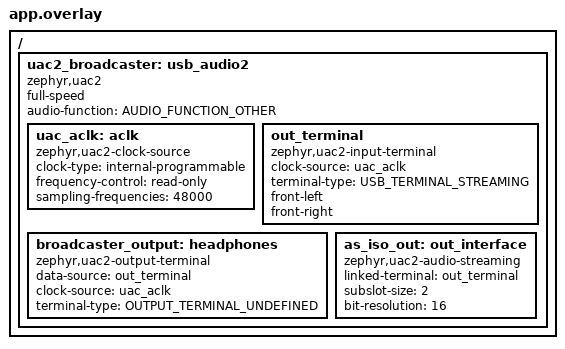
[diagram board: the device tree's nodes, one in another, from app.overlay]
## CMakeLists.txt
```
# SPDX-License-Identifier: Apache-2.0

cmake_minimum_required(VERSION 3.28.0)
find_package(Zephyr REQUIRED HINTS $ENV{ZEPHYR_BASE})
project(bap_broadcast_source)

target_sources(app PRIVATE
  src/main.c
)

target_sources_ifdef(CONFIG_AUDIO_INPUT_STREAM app PRIVATE src/audio_in.c)
target_sources_ifdef(CONFIG_CHAN_MAP_UPDATE app PRIVATE src/chan_map.c)
target_sources_ifdef(CONFIG_VS_FATAL_PRINT app PRIVATE src/vs_fatal.c)

if(CONFIG_AUDIO_INPUT_TIMED AND CONFIG_USE_USB_AUDIO_INPUT)
  target_sources(app PRIVATE src/usb_sof_nrf.c)
endif()

if(CONFIG_USE_USB_AUDIO_INPUT)
  include(${ZEPHYR_BASE}/samples/subsys/usb/common/common.cmake)
endif()
```

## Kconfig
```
# Copyright (c) 2023 Demant A/S
# Copyright (c) 2023 Nordic Semiconductor ASA
# SPDX-License-Identifier: Apache-2.0

mainmenu "Bluetooth: Broadcast Audio Source"

choice BAP_LC3_PRESET
	prompt "The BAP LC3 Preset to be used"
	default BAP_BROADCAST_16_2_1

config BAP_BROADCAST_16_2_1
	bool "BAP_LC3_BROADCAST_PRESET_16_2_1 preset"
	help
	  Using the BAP_LC3_BROADCAST_PRESET_16_2_1 preset.

config BAP_BROADCAST_24_2_1
	bool "BAP_LC3_BROADCAST_PRESET_24_2_1 preset"
	help
	  Using the BAP_LC3_BROADCAST_PRESET_24_2_1 preset.

config BAP_BROADCAST_48_2_1
	bool "BAP_LC3_BROADCAST_PRESET_48_2_1 preset"
	help
	  Using the BAP_LC3_BROADCAST_PRESET_48_2_1 preset.

endchoice

config ENABLE_LC3
	bool "Enable the LC3 codec"
	# By default let's enable it in the platforms we know are capable of supporting it
	default y
	depends on CPU_HAS_FPU && \
		(ARCH_POSIX || \
		SOC_COMPATIBLE_NRF52X || \
		SOC_COMPATIBLE_NRF5340_CPUAPP || \
		SOC_COMPATIBLE_NRF54LX || \
		SOC_MIMXRT1062 || \
		SOC_SERIES_ESP32S31)
	select LIBLC3
	select FPU

config ISO_PACKING_INTERLEAVED
	bool "Use interleaved packing"
	help
	  Use interleaved packing between BIS ISO stream subevents.

config USE_USB_AUDIO_INPUT
	bool "Use USB Audio as input"
	# By default, use the USB Audio path is disabled.
	depends on ENABLE_LC3
	select USB_DEVICE_STACK_NEXT
	select USBD_AUDIO2_CLASS

config BROADCAST_CODE
	string "The broadcast code (if any) to use for encrypted broadcast"
	default ""
	help
	   Setting a non-empty string for this option will encrypt the broadcast using this
	   string as the broadcast code. The length of the string shall be between 1 and 16 octets.

config STATIC_BROADCAST_ID
	bool "Use static broadcast ID"
	default y
	help
	   Enabling this option will make the application use static broadcast ID, as opposed to a
	   randomly generated one.

config BROADCAST_ID
	hex "The static broadcast ID to use"
	range 0x000000 0xFFFFFF
	depends on STATIC_BROADCAST_ID
	default 0x123456
	help
	   This is the 3-octet broadcast ID advertised if static broadcast IDs are enabled.

config BROADCAST_NAME
	string "Bluetooth broadcast name"
	default BT_DEVICE_NAME
	help
	   Bluetooth broadcast name. Can be used for scanning device that displays information on
	   the available broadcast sources. Name length range is 4 to 32.

# Source common USB sample options used to initialize new experimental USB device stack.
# The scope of these options is limited to USB samples in project tree,
# you cannot use them in your own application.
source "samples/subsys/usb/common/Kconfig.sample_usbd"

source "Kconfig.zephyr"
```

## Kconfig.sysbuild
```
# Copyright 2023 Nordic Semiconductor ASA
# SPDX-License-Identifier: Apache-2.0

source "share/sysbuild/Kconfig"

config NET_CORE_BOARD
	string
	default "nrf5340dk/nrf5340/cpunet" if "$(BOARD)" = "nrf5340dk"
	default "nrf5340_audio_dk/nrf5340/cpunet" if "$(BOARD)" = "nrf5340_audio_dk"
	default "nrf54h20dk/nrf54h20/cpurad" if "$(BOARD)" = "nrf54h20dk"
	default "nrf5340bsim/nrf5340/cpunet" if $(BOARD_TARGET_STRING) = "NRF5340BSIM_NRF5340_CPUAPP"

config NET_CORE_IMAGE_HCI_IPC
	bool "HCI IPC image on network core"
	default y
	depends on NET_CORE_BOARD != ""
```

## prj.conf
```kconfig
CONFIG_MAIN_STACK_SIZE=2048

CONFIG_BT=y
CONFIG_UTF8=y
CONFIG_BT_AUDIO=y
CONFIG_BT_ISO_BROADCASTER=y
CONFIG_BT_BAP_BROADCAST_SOURCE=y

# Allow simultaneous connectable advertising so that a remote central can
# connect while the broadcast source keeps streaming LE Audio. Three
# advertising sets run in parallel: the non-connectable extended broadcast
# audio set, a connectable extended set, and a connectable legacy set.
# Button 0 enables or disables the connectable advertising, off at boot.
CONFIG_BT_PERIPHERAL=y
CONFIG_BT_MAX_CONN=2
CONFIG_BT_EXT_ADV_MAX_ADV_SET=3

# Continuous active extended scanning, toggled by button 2 and off at boot.
# Its auxiliary channel receptions provide channel metrics for the channel map.
CONFIG_BT_OBSERVER=y

# Host ACL buffers to match the Controller maximum data length
CONFIG_BT_BUF_ACL_RX_SIZE=255
CONFIG_BT_BUF_ACL_TX_SIZE=251

CONFIG_BT_ISO_MAX_CHAN=2
CONFIG_BT_BAP_BROADCAST_SRC_STREAM_COUNT=2
# Two streams in one subgroup (stereo)
CONFIG_BT_BAP_BROADCAST_SRC_SUBGROUP_COUNT=1

# Uncomment below to use Broadcast ISO interleaved packing
# CONFIG_ISO_PACKING_INTERLEAVED=y

CONFIG_BT_ISO_TX_BUF_COUNT=6
CONFIG_BT_ISO_TX_MTU=155

CONFIG_BT_DEVICE_NAME="Broadcast Audio Source"

CONFIG_LOG=y
CONFIG_LOG_BUFFER_SIZE=4096

CONFIG_ASSERT=y
```

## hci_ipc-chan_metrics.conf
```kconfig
# Channel metrics vendor-specific event, used to update the channel map
CONFIG_BT_CTLR_CHAN_METRICS_EVENT=y
```

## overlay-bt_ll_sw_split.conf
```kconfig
# Zephyr Bluetooth Controller
CONFIG_BT_LL_SW_SPLIT=y

# Zephyr Controller tested maximum advertising data that can be set in a single HCI command
CONFIG_BT_CTLR_ADV_DATA_LEN_MAX=191

# Enable support for Broadcast ISO in Zephyr Bluetooth Controller
CONFIG_BT_CTLR_ADV_ISO=y
CONFIG_BT_CTLR_ADV_ISO_SEQUENTIAL=y
CONFIG_BT_CTLR_ADV_ISO_INTERLEAVED=y

# Sufficient ISO PDU length for any BAP LC3 presets (155)
CONFIG_BT_CTLR_ADV_ISO_PDU_LEN_MAX=155

# Number of supported streams
CONFIG_BT_CTLR_ADV_ISO_STREAM_MAX=2
CONFIG_BT_CTLR_ISOAL_SOURCES=2

# Support the highest SDU size required by any BAP LC3 presets (155) + 8 bytes of HCI ISO Data
# packet overhead (the Packet_Sequence_Number, ISO_SDU_Length, Packet_Status_Flag fields; and
# the optional Time_Stamp field, if supplied)
CONFIG_BT_CTLR_ISO_TX_BUFFER_SIZE=163
CONFIG_BT_CTLR_ISO_TX_SDU_LEN_MAX=155

# Use minimal time reservation for advertising radio events, successfully fit 155 Byte stereo BAP
# 48_6_1 preset and extended advertisements :-)
# Use the below when advertising is started after advertising data has been set and the data will
# not be updated to large size once advertising has been started
CONFIG_BT_CTLR_ADVANCED_FEATURES=y
CONFIG_BT_CTLR_ADV_RESERVE_MAX=n
CONFIG_BT_CTLR_PERIPHERAL_RESERVE_MAX=n

# Use the below to have auxiliary PDUs dynamically be placed in-between ISO intervals and hence
# permit large BIG event lengths (and hence, possibility to have pre-transmissions)
CONFIG_BT_CTLR_ADV_SLOT_WINDOW=y
CONFIG_BT_CTLR_ADV_AUX_SLOT_WINDOW_DRIFT=y

CONFIG_BT_CTLR_ADV_ISO_RESERVE_MAX=n
CONFIG_BT_CTLR_ADV_ISO_SLOT_WINDOW_JITTER=y

CONFIG_BT_CTLR_LLL_PRIO=0
CONFIG_BT_CTLR_ULL_HIGH_PRIO=1
CONFIG_BT_CTLR_ULL_LOW_PRIO=2

CONFIG_BT_CTLR_LLL_PREPARE_AT_MARGIN=y
CONFIG_BT_CTLR_RADIO_TIMER_ISR=y
CONFIG_BT_CTLR_SW_SWITCH_SINGLE_TIMER=n

# Enable in-system tests and profiling
# CONFIG_BT_CTLR_TEST=y
# CONFIG_BT_CTLR_PROFILE_ISR=y

CONFIG_BT_CTLR_ASSERT_OPTIMIZE_FOR_SIZE=n

# Extended scanning in parallel with Broadcast ISO
CONFIG_BT_CTLR_SCAN_AUX_SET=3
CONFIG_BT_CTLR_SCAN_AUX_SYNC_RESERVE_MIN=y
CONFIG_BT_CTLR_SCAN_UNRESERVED=y
CONFIG_BT_CTLR_SCAN_SLOT_WINDOW=y

# Channel metrics vendor-specific event, used to update the channel map
CONFIG_BT_CTLR_CHAN_METRICS_EVENT=y
```

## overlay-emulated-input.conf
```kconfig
# Emulated USB host feeding the audio input path, for testing without USB hardware
CONFIG_AUDIO_INPUT_EMULATED=y
CONFIG_BAP_BROADCAST_8_2_1=y
```

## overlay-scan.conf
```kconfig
# Continuous active extended scanning from boot
CONFIG_SCAN_BACKGROUND=y
```

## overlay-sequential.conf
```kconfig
CONFIG_ISO_PACKING_INTERLEAVED=n
```

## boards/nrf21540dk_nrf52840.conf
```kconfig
# Use USB Audio as audio source
CONFIG_USE_USB_AUDIO_INPUT=y
CONFIG_SAMPLE_USBD_PRODUCT="USB Broadcast Audio nRF21540DK"

CONFIG_UDC_DRIVER_LOG_LEVEL_WRN=y
CONFIG_USBD_LOG_LEVEL_WRN=y
CONFIG_USBD_UAC2_LOG_LEVEL_WRN=y
```

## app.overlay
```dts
/*
 * Copyright (c) 2025 Nordic Semiconductor ASA
 *
 * SPDX-License-Identifier: Apache-2.0
 */

#include <zephyr/dt-bindings/usb/audio.h>

/ {
	uac2_broadcaster: usb_audio2 {
		compatible = "zephyr,uac2";
		full-speed;
		audio-function = <AUDIO_FUNCTION_OTHER>;
		status = "okay";

		/* Clock supporting 48KHz
		 *
		 * For simplicity we claim support for 48KHz only and then downsample if needed
		 */
		uac_aclk: aclk {
			compatible = "zephyr,uac2-clock-source";
			clock-type = "internal-programmable";
			frequency-control = "read-only";
			sampling-frequencies = <48000>;
		};

		/* USB Audio terminal from USB host to USB device */
		out_terminal: out_terminal {
			compatible = "zephyr,uac2-input-terminal";
			clock-source = <&uac_aclk>;
			terminal-type = <USB_TERMINAL_STREAMING>;
			front-left;
			front-right;
		};

		/* The broadcaster_output terminal defines what we are sending over Bluetooth */
		broadcaster_output: headphones {
			compatible = "zephyr,uac2-output-terminal";
			data-source = <&out_terminal>;
			clock-source = <&uac_aclk>;
			terminal-type = <OUTPUT_TERMINAL_UNDEFINED>;
		};

		as_iso_out: out_interface {
			compatible = "zephyr,uac2-audio-streaming";
			linked-terminal = <&out_terminal>;
			subslot-size = <2>;
			bit-resolution = <16>;
		};
	};
};
```

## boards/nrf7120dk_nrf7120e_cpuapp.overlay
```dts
/*
 * Copyright (c) 2026 Nordic Semiconductor ASA
 *
 * SPDX-License-Identifier: Apache-2.0
 */

#include "../app.overlay"
```

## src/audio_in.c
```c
/*
 * Copyright (c) 2025 Nordic Semiconductor ASA
 *
 * SPDX-License-Identifier: Apache-2.0
 *
 * Audio input path between an asynchronous 48 kHz stereo producer (USB host) and the ISO
 * stream consumer. The ISO stream is the clock master: the consumer takes one SDU frame per
 * channel each time the controller completes an SDU. The buffer fill level, sampled just
 * before each take, integrates the rate difference between producer and consumer and drives
 * a PI loop that sets the UAC2 explicit feedback value. If the host does not follow the
 * feedback, a single sample is dropped or repeated per SDU to keep the buffer within bounds.
 *
 * With CONFIG_AUDIO_INPUT_TIMED the USB SOF times and the SDU transmission times share the
 * controller time base. The feedback value is then the measured number of samples per SOF
 * period at the ISO stream rate, and a slow proportional loop holds the buffer level at the
 * nominal encode time of each SDU, interpolated from the SOF timeline, on the target. This
 * level is free of USB packet and thread scheduling jitter, so the buffer stays at its target
 * without dropped or repeated samples.
 */

#include <errno.h>
#include <stdbool.h>
#include <stddef.h>
#include <stdint.h>
#include <string.h>

#include <zephyr/kernel.h>
#include <zephyr/sys/atomic.h>
#include <zephyr/sys/printk.h>
#include <zephyr/sys/ring_buffer.h>
#include <zephyr/sys/util.h>

#if defined(CONFIG_AUDIO_INPUT_TIMED)
#include <zephyr/drivers/timer/nrf_grtc_timer.h>
#endif /* CONFIG_AUDIO_INPUT_TIMED */

#include "audio_in.h"

#define FRAME_SAMPLES_MAX 480U /* 10 ms at 48 kHz */
#define RING_FRAMES       6U
#define RING_BYTES        (FRAME_SAMPLES_MAX * RING_FRAMES * sizeof(int16_t))
#define PUT_CHUNK_MAX     64U

/* Fill level (per channel, in SDU frames) before a take: 2 frames leaves one frame of margin
 * for producer delivery jitter after the take. Samples are dropped above 3.5 frames, which
 * tolerates late consumer wakeups, and repeated below 1.5 frames.
 */
#define TARGET_FRAMES 2U

/* PI gains, error in 48 kHz samples, output in Q10.14 LSB (1 LSB ~ 1.27 ppm).
 * Kp gives ~4 s time constant, Ki gives a damping ratio of ~0.7.
 */
#define PI_KP        4.0f
#define PI_KI        0.5f
#define FB_LIMIT_PPM 1000

/* SOF timeline: one entry per SOF, (time, samples written). The consumer reads back at most
 * TL_DEPTH entries so that the producer does not overwrite an entry being read.
 */
#define TL_SIZE  32U
#define TL_DEPTH (TL_SIZE - 4U)

#define SOF_PERIOD_US 1000U
/* A longer SOF gap (bus suspend, host stall) restarts the SOF rate measurement */
#define SOF_GAP_US    100000U

/* Rate measured over the last RATE_WINDOW..2*RATE_WINDOW SOF periods, ~0.5 ppm resolution with
 * 1 us time stamps; a first estimate is used after RATE_MIN_FRAMES.
 */
#define RATE_WINDOW_FRAMES 2048U
#define RATE_MIN_FRAMES    128U

/* The buffer level is evaluated this long before the average encode time, so that it is
 * interpolated between SOF time stamps already received.
 */
#define PHASE_GUARD_US     2000
/* Encode lead time average: 1/16 weight per SDU */
#define LEAD_EMA_WEIGHT    0.0625f
/* Phase loop gain, error in 48 kHz samples, output in Q10.14 LSB: ~4 s time constant */
#define PHASE_KP           4.0f
#define PHASE_LIMIT_PPM    200

static struct ring_buf rings[AUDIO_IN_CHANNELS];
static uint8_t ring_mem[AUDIO_IN_CHANNELS][RING_BYTES];

static uint32_t ratio;
static size_t frame_n;
static uint32_t sdus_per_sec;
static uint32_t target;
static uint32_t slip_above;
static uint32_t repeat_below;

static atomic_t feedback = ATOMIC_INIT(AUDIO_IN_FB_NOMINAL);
static atomic_t flush_req;

/* Producer state */
static int32_t dec_acc[AUDIO_IN_CHANNELS];
static uint32_t dec_cnt;
static atomic_t overruns;
/* Samples per channel written to the ring buffer, wrapping */
static uint32_t written;

/* Producer input metrics, cleared by the producer when the consumer requests it */
struct in_metrics {
	uint32_t packets;
	uint32_t samples;
	uint32_t pkt_min;
	uint32_t pkt_max;
};
static struct in_metrics in_m = {.pkt_min = UINT32_MAX};
static atomic_t in_m_clear;

/* Consumer state */
static bool primed;
static float pi_integral;
static uint32_t period_cnt;
static uint32_t silent;
static uint64_t fill_sum;
static uint32_t fill_sum_n;
static uint32_t fill_min = UINT32_MAX;
static uint32_t fill_max;
static uint32_t underruns;
static uint32_t slips;
static uint32_t repeats;
static uint32_t primes;
/* Samples per channel removed from the ring buffer, wrapping */
static uint32_t removed;

#if defined(CONFIG_AUDIO_INPUT_TIMED)
struct tl_entry {
	uint32_t t;
	uint32_t s;
};

/* Producer timed state */
static struct tl_entry tl[TL_SIZE];
static atomic_t tl_head;
static bool sof_valid;
static uint32_t sof_last_t;
static uint32_t sof_frames;
static uint32_t rate_a_t;
static uint32_t rate_a_k;
static uint32_t rate_b_t;
static uint32_t rate_b_k;
static atomic_t fb_rate;
static atomic_t sof_skipped;
static atomic_t sof_restarts;

/* SOF time stamp metrics, in the controller time base; cleared like in_m */
struct sof_metrics {
	bool valid;
	uint32_t t_first;
	uint32_t t_last;
	/* SOF periods between t_first and t_last */
	uint32_t frames;
	/* Single period intervals and their range */
	uint32_t periods;
	uint32_t dt_min;
	uint32_t dt_max;
};
static struct sof_metrics sof_m = {.dt_min = UINT32_MAX};
static atomic_t sof_m_clear;
static int32_t rate_ppm_prev;

/* Consumer timed state */
static bool lead_valid;
static float lead_us;
static int32_t lead_ref;
static bool aligned;
static float phase_sum;
static uint32_t phase_n;
static float phase_min = (float)INT32_MAX;
static float phase_max = (float)INT32_MIN;
static int32_t lead_min = INT32_MAX;
static int32_t lead_max = INT32_MIN;
static int64_t lead_sum;
static uint32_t lead_n;
static uint32_t late;
static uint32_t no_timeline;
static uint32_t aligns;
#endif /* CONFIG_AUDIO_INPUT_TIMED */

int audio_in_init(uint32_t rate_hz, size_t frame_samples)
{
	if ((rate_hz == 0U) || ((AUDIO_IN_RATE_HZ % rate_hz) != 0U) || (frame_samples < 2U) ||
	    (frame_samples > FRAME_SAMPLES_MAX) || ((rate_hz % frame_samples) != 0U)) {
		return -EINVAL;
	}

	ratio = AUDIO_IN_RATE_HZ / rate_hz;
	frame_n = frame_samples;
	sdus_per_sec = rate_hz / frame_samples;
	target = TARGET_FRAMES * frame_samples;
	slip_above = target + frame_samples + (frame_samples / 2U);
	repeat_below = target - (frame_samples / 2U);

	for (size_t i = 0U; i < AUDIO_IN_CHANNELS; i++) {
		ring_buf_init(&rings[i], sizeof(ring_mem[i]), ring_mem[i]);
	}

	printk("Audio in: ratio %u, frame %zu, target %u, capacity %u samples\n", ratio, frame_n,
	       target, ring_buf_capacity_get(&rings[0]) / (uint32_t)sizeof(int16_t));

	return 0;
}

void audio_in_put(const int16_t *pcm, size_t frames)
{
	int16_t out[AUDIO_IN_CHANNELS][PUT_CHUNK_MAX];

	if (atomic_cas(&in_m_clear, 1, 0)) {
		in_m = (struct in_metrics){.pkt_min = UINT32_MAX};
	}

	/* One call per USB packet */
	in_m.packets++;
	in_m.samples += (uint32_t)frames;
	in_m.pkt_min = MIN(in_m.pkt_min, (uint32_t)frames);
	in_m.pkt_max = MAX(in_m.pkt_max, (uint32_t)frames);

	while (frames > 0U) {
		const size_t chunk = MIN(frames, PUT_CHUNK_MAX);
		uint32_t bytes;
		size_t n = 0U;

		/* Phase continuous boxcar decimation; chunks need not be a multiple of ratio */
		for (size_t i = 0U; i < chunk; i++) {
			for (size_t ch = 0U; ch < AUDIO_IN_CHANNELS; ch++) {
				dec_acc[ch] += pcm[(i * AUDIO_IN_CHANNELS) + ch];
			}

			dec_cnt++;
			if (dec_cnt == ratio) {
				for (size_t ch = 0U; ch < AUDIO_IN_CHANNELS; ch++) {
					out[ch][n] = (int16_t)(dec_acc[ch] / (int32_t)ratio);
					dec_acc[ch] = 0;
				}
				dec_cnt = 0U;
				n++;
			}
		}

		pcm += chunk * AUDIO_IN_CHANNELS;
		frames -= chunk;

		if (n == 0U) {
			continue;
		}

		/* Keep channels aligned: write all or nothing */
		bytes = n * sizeof(int16_t);
		if ((ring_buf_space_get(&rings[0]) < bytes) ||
		    (ring_buf_space_get(&rings[1]) < bytes)) {
			atomic_inc(&overruns);
			continue;
		}

		for (size_t ch = 0U; ch < AUDIO_IN_CHANNELS; ch++) {
			(void)ring_buf_put(&rings[ch], (uint8_t *)out[ch], bytes);
		}
		written += (uint32_t)n;
	}
}

#if defined(CONFIG_AUDIO_INPUT_TIMED)
static void sof_restart(uint32_t t_us)
{
	sof_valid = true;
	sof_last_t = t_us;
	sof_frames = 0U;
	rate_a_t = t_us;
	rate_a_k = 0U;
	rate_b_t = t_us;
	rate_b_k = 0U;
	atomic_inc(&sof_restarts);
}

void audio_in_sof(uint32_t t_us)
{
	const uint32_t dt = t_us - sof_last_t;
	uint32_t frames;
	uint32_t dk;

	if (atomic_cas(&sof_m_clear, 1, 0)) {
		sof_m = (struct sof_metrics){.dt_min = UINT32_MAX};
	}

	if (!sof_valid || (dt > SOF_GAP_US)) {
		sof_restart(t_us);
		/* Measure the host clock from here on */
		sof_m.valid = true;
		sof_m.t_first = t_us;
		sof_m.t_last = t_us;
		sof_m.frames = 0U;
		return;
	}

	if (!sof_m.valid) {
		sof_m.valid = true;
		sof_m.t_first = sof_last_t;
		sof_m.t_last = sof_last_t;
	}

	if (dt < (SOF_PERIOD_US / 2U)) {
		return;
	}

	/* The capture may be read late or be from a later SOF than the one being handled;
	 * the frame count follows from the time stamps.
	 */
	dk = (dt + (SOF_PERIOD_US / 2U)) / SOF_PERIOD_US;
	sof_frames += dk;
	sof_last_t = t_us;

	sof_m.frames += dk;
	sof_m.t_last = t_us;

	if (dk == 1U) {
		const atomic_val_t head = atomic_get(&tl_head);

		sof_m.periods++;
		sof_m.dt_min = MIN(sof_m.dt_min, dt);
		sof_m.dt_max = MAX(sof_m.dt_max, dt);

		tl[(uint32_t)head % TL_SIZE] = (struct tl_entry){.t = t_us, .s = written};
		(void)atomic_set(&tl_head, head + 1);
	} else {
		/* Samples written are not known at the captured SOF; use it for rate only */
		atomic_inc(&sof_skipped);
	}

	if ((sof_frames - rate_b_k) >= RATE_WINDOW_FRAMES) {
		rate_a_t = rate_b_t;
		rate_a_k = rate_b_k;
		rate_b_t = t_us;
		rate_b_k = sof_frames;
	}

	frames = sof_frames - rate_a_k;
	if (frames >= RATE_MIN_FRAMES) {
		/* Samples per SOF period at exactly AUDIO_IN_RATE_HZ in the controller time base */
		const uint64_t num = (uint64_t)AUDIO_IN_FB_NOMINAL * (t_us - rate_a_t);
		const uint64_t den = (uint64_t)frames * SOF_PERIOD_US;

		(void)atomic_set(&fb_rate, (atomic_val_t)((num + (den / 2U)) / den));
	}
}

/* Buffer level at time t_us for the samples removed so far, interpolated on the SOF timeline */
static bool level_at(uint32_t t_us, float *level)
{
	const atomic_val_t head = atomic_get(&tl_head);
	const uint32_t n = MIN((uint32_t)head, TL_DEPTH);
	bool found = false;
	struct tl_entry a;
	struct tl_entry b;

	if (n < 2U) {
		return false;
	}

	b = tl[(uint32_t)(head - 1) % TL_SIZE];
	if ((int32_t)(t_us - b.t) >= 0) {
		/* Later than the last SOF: no extrapolation */
		*level = (float)(int32_t)(b.s - removed);
		found = true;
	}

	for (uint32_t i = 2U; !found && (i <= n); i++) {
		a = tl[(uint32_t)(head - (atomic_val_t)i) % TL_SIZE];
		if ((int32_t)(t_us - a.t) >= 0) {
			const float frac = (float)(int32_t)(t_us - a.t) /
					   (float)(int32_t)(b.t - a.t);

			*level = (float)(int32_t)(a.s - removed) +
				 ((float)(int32_t)(b.s - a.s) * frac);
			found = true;
		}
		b = a;
	}

	/* Entries read may have been overwritten meanwhile */
	if ((uint32_t)(atomic_get(&tl_head) - head) > (TL_SIZE - TL_DEPTH)) {
		return false;
	}

	return found;
}
#else
void audio_in_sof(uint32_t t_us)
{
	ARG_UNUSED(t_us);
}
#endif /* CONFIG_AUDIO_INPUT_TIMED */

static uint32_t fill_get(void)
{
	return MIN(ring_buf_size_get(&rings[0]), ring_buf_size_get(&rings[1])) / sizeof(int16_t);
}

static void discard(uint32_t samples)
{
	samples = MIN(samples, fill_get());

	for (size_t ch = 0U; ch < AUDIO_IN_CHANNELS; ch++) {
		ring_buf_consume(&rings[ch], samples * sizeof(int16_t));
	}

	removed += samples;
}

#if defined(CONFIG_AUDIO_INPUT_TIMED)
static bool control_update_timed(void)
{
	const float phase_limit = (float)AUDIO_IN_FB_NOMINAL * PHASE_LIMIT_PPM / 1000000.0f;
	const float fb_limit = (float)AUDIO_IN_FB_NOMINAL * FB_LIMIT_PPM / 1000000.0f;
	const int32_t rate = (int32_t)atomic_get(&fb_rate);
	float err;
	float fb;

	if ((phase_n == 0U) || (rate == 0)) {
		phase_sum = 0.0f;
		phase_n = 0U;
		return false;
	}

	/* Error in 48 kHz samples */
	err = (phase_sum / (float)phase_n) * (float)ratio;
	phase_sum = 0.0f;
	phase_n = 0U;

	fb = (float)(rate - (int32_t)AUDIO_IN_FB_NOMINAL) +
	     CLAMP(-(PHASE_KP * err), -phase_limit, phase_limit);
	fb = CLAMP(fb, -fb_limit, fb_limit);

	atomic_set(&feedback, (atomic_val_t)((int32_t)AUDIO_IN_FB_NOMINAL + (int32_t)fb));

	/* Continue from the same value if the time stamps are lost */
	pi_integral = -fb;

	return true;
}
#endif /* CONFIG_AUDIO_INPUT_TIMED */

static void control_update(void)
{
	const float fb_limit = (float)AUDIO_IN_FB_NOMINAL * FB_LIMIT_PPM / 1000000.0f;
	float err;
	float fb;

#if defined(CONFIG_AUDIO_INPUT_TIMED)
	if (primed && control_update_timed()) {
		fill_sum = 0U;
		fill_sum_n = 0U;
		return;
	}
#endif /* CONFIG_AUDIO_INPUT_TIMED */

	if ((fill_sum_n == 0U) || !primed) {
		fill_sum = 0U;
		fill_sum_n = 0U;
		return;
	}

	/* Error in 48 kHz samples */
	err = (((float)fill_sum / (float)fill_sum_n) - (float)target) * (float)ratio;
	fill_sum = 0U;
	fill_sum_n = 0U;

	pi_integral = CLAMP(pi_integral + (PI_KI * err), -fb_limit, fb_limit);
	fb = CLAMP(-(PI_KP * err) - pi_integral, -fb_limit, fb_limit);

	atomic_set(&feedback, (atomic_val_t)((int32_t)AUDIO_IN_FB_NOMINAL + (int32_t)fb));
}

/* x / nominal - 1 in hundredths of ppm */
static int64_t centi_ppm(int64_t x, int64_t nominal)
{
	return ((x - nominal) * 100000000LL) / nominal;
}

#if defined(CONFIG_AUDIO_INPUT_TIMED)
static void metrics_print_timed(const struct in_metrics *in)
{
	const struct sof_metrics sof = sof_m;
	const int32_t rate = (int32_t)atomic_get(&fb_rate);
	char s1[24];
	char s2[24];

	(void)atomic_set(&sof_m_clear, 1);

	if (sof.valid && (sof.frames > 0U) && (sof.t_last != sof.t_first)) {
		const uint32_t span = sof.t_last - sof.t_first;
		/* Mean SOF period in ns, controller clock */
		const uint32_t mean_ns = (uint32_t)(((uint64_t)span * 1000U) / sof.frames);
		const int32_t mean_us = (int32_t)((mean_ns + 500U) / 1000U);

		/* Host clock relative to the controller clock: nominal / measured SOF period */
		printk("  USB SOF: %u frames, period %u.%03u us, min %u max %u us (jitter %d..%+d "
		       "us), host clock %s ppm\n",
		       sof.frames, mean_ns / 1000U, mean_ns % 1000U,
		       (sof.periods > 0U) ? sof.dt_min : 0U, sof.dt_max,
		       (sof.periods > 0U) ? ((int32_t)sof.dt_min - mean_us) : 0,
		       (sof.periods > 0U) ? ((int32_t)sof.dt_max - mean_us) : 0,
		       audio_in_centi_str(s1, sizeof(s1),
					  centi_ppm((int64_t)sof.frames * SOF_PERIOD_US,
						    (int64_t)span)));

		if (in->packets > 0U) {
			/* Samples per packet times packets per controller second */
			const uint64_t c_hz = ((uint64_t)in->samples * sof.frames * 100000000ULL) /
					      ((uint64_t)in->packets * span);

			printk("  USB input rate %u.%02u Hz in controller clock (%s ppm)\n",
			       (uint32_t)(c_hz / 100U), (uint32_t)(c_hz % 100U),
			       audio_in_centi_str(s1, sizeof(s1),
						  centi_ppm((int64_t)c_hz,
							    (int64_t)AUDIO_IN_RATE_HZ * 100)));
		}
	} else {
		printk("  USB SOF: no time stamps\n");
	}

	if (rate != 0) {
		/* SOF period over the rate window, as host clock offset */
		const int32_t host_cppm = (int32_t)-centi_ppm(rate, AUDIO_IN_FB_NOMINAL);

		printk("  clock drift: host %s ppm over %u..%u ms, change %s ppm, sof skip %u "
		       "restart %u\n",
		       audio_in_centi_str(s1, sizeof(s1), host_cppm), RATE_WINDOW_FRAMES,
		       2U * RATE_WINDOW_FRAMES,
		       audio_in_centi_str(s2, sizeof(s2), (int64_t)host_cppm - rate_ppm_prev),
		       (uint32_t)atomic_get(&sof_skipped), (uint32_t)atomic_get(&sof_restarts));
		rate_ppm_prev = host_cppm;
	}

	if (lead_n > 0U) {
		printk("  encode lead: %d..%d avg %d us (jitter %d us), level ref %d us, late %u\n",
		       lead_min, lead_max, (int32_t)(lead_sum / lead_n), lead_max - lead_min,
		       lead_ref, late);
	}

	if (phase_max >= phase_min) {
		printk("  level err %d..%d samples, align %u, no timeline %u\n",
		       (int32_t)phase_min, (int32_t)phase_max, aligns, no_timeline);
	}

	phase_min = (float)INT32_MAX;
	phase_max = (float)INT32_MIN;
	lead_min = INT32_MAX;
	lead_max = INT32_MIN;
	lead_sum = 0;
	lead_n = 0U;
}
#endif /* CONFIG_AUDIO_INPUT_TIMED */

void audio_in_metrics_print(void)
{
	const int32_t fb = (int32_t)atomic_get(&feedback);
	const struct in_metrics in = in_m;
	char s1[24];

	/* The producer clears its metrics at its next call */
	(void)atomic_set(&in_m_clear, 1);

	printk("  audio in: fb %d (%s ppm) fill %u..%u target %u silent %u underrun %u "
	       "overrun %u slip %u repeat %u prime %u\n",
	       fb, audio_in_centi_str(s1, sizeof(s1), centi_ppm(fb, AUDIO_IN_FB_NOMINAL)),
	       (fill_min <= fill_max) ? fill_min : 0U, fill_max, target, silent, underruns,
	       (uint32_t)atomic_get(&overruns), slips, repeats, primes);

	if (in.packets > 0U) {
		/* Average samples per 1 ms packet: the rate in the host clock */
		const uint64_t h_hz = ((uint64_t)in.samples * 100000ULL) / in.packets;

		printk("  USB input: %u packets, %u..%u samples/packet, %u.%02u Hz in host clock\n",
		       in.packets, in.pkt_min, in.pkt_max, (uint32_t)(h_hz / 100U),
		       (uint32_t)(h_hz % 100U));
	} else {
		printk("  USB input: no data\n");
	}

	fill_min = UINT32_MAX;
	fill_max = 0U;

#if defined(CONFIG_AUDIO_INPUT_TIMED)
	metrics_print_timed(&in);
#endif /* CONFIG_AUDIO_INPUT_TIMED */
}

#if defined(CONFIG_AUDIO_INPUT_TIMED)
static void phase_update(float err, uint32_t *fill)
{
	if (!aligned) {
		/* One time phase alignment after priming, before the loop takes over */
		if (err > (float)(frame_n / 4U)) {
			const uint32_t excess = MIN((uint32_t)err, *fill - frame_n);

			discard(excess);
			*fill -= excess;
			err -= (float)excess;
			aligns++;
		}
		aligned = true;
	}

	phase_sum += err;
	phase_n++;
	phase_min = MIN(phase_min, err);
	phase_max = MAX(phase_max, err);
}
#endif /* CONFIG_AUDIO_INPUT_TIMED */

static void get_frame(int16_t *left, int16_t *right, bool timed, uint32_t t_level)
{
	int16_t *out[AUDIO_IN_CHANNELS] = {left, right};
	size_t n = frame_n;
	uint32_t fill;

	if (atomic_cas(&flush_req, 1, 0)) {
		discard(fill_get());
		primed = false;
	}

#if defined(CONFIG_AUDIO_INPUT_TIMED)
	if (!primed) {
		aligned = false;
	}
#endif /* CONFIG_AUDIO_INPUT_TIMED */

	fill = fill_get();

	if (!primed && (fill >= target)) {
		/* The producer may run before the ISO stream starts and the first takes are not
		 * yet at their steady phase; start in the middle of the slip/repeat band and let
		 * the control loop settle on the target.
		 */
		const uint32_t start = (slip_above + repeat_below) / 2U;

		if (fill > start) {
			discard(fill - start);
			fill = start;
		}
		primed = true;
		primes++;
	}

	fill_min = MIN(fill_min, fill);
	fill_max = MAX(fill_max, fill);

	if (!primed) {
		goto silence;
	}

	if (fill < frame_n) {
		underruns++;
		primed = false;
		goto silence;
	}

#if defined(CONFIG_AUDIO_INPUT_TIMED)
	if (timed) {
		float level;

		if (level_at(t_level, &level)) {
			phase_update(level - (float)target, &fill);
		} else {
			no_timeline++;
		}
	}
#else
	ARG_UNUSED(timed);
	ARG_UNUSED(t_level);
#endif /* CONFIG_AUDIO_INPUT_TIMED */

	fill_sum += fill;
	fill_sum_n++;

	if (fill > slip_above) {
		discard(1U);
		slips++;
	} else if (fill < repeat_below) {
		n--;
		repeats++;
	}

	for (size_t ch = 0U; ch < AUDIO_IN_CHANNELS; ch++) {
		(void)ring_buf_get(&rings[ch], (uint8_t *)out[ch], n * sizeof(int16_t));
		if (n < frame_n) {
			out[ch][n] = out[ch][n - 1U];
		}
	}
	removed += (uint32_t)n;

	goto account;

silence:
	silent++;
	(void)memset(left, 0, frame_n * sizeof(int16_t));
	(void)memset(right, 0, frame_n * sizeof(int16_t));

account:
	period_cnt++;
	if (period_cnt >= sdus_per_sec) {
		period_cnt = 0U;
		control_update();
	}
}

void audio_in_get(int16_t *left, int16_t *right)
{
	get_frame(left, right, false, 0U);
}

void audio_in_get_timed(int16_t *left, int16_t *right, uint32_t t_tx_us)
{
#if defined(CONFIG_AUDIO_INPUT_TIMED)
	const uint32_t now = (uint32_t)z_nrf_grtc_timer_read();
	const int32_t lead = (int32_t)(t_tx_us - now);

	/* Encode lead time before the SDU is sent on air */
	if (!lead_valid) {
		lead_us = (float)lead;
		lead_valid = true;
	} else {
		lead_us += ((float)lead - lead_us) * LEAD_EMA_WEIGHT;
	}

	lead_min = MIN(lead_min, lead);
	lead_max = MAX(lead_max, lead);
	lead_sum += lead;
	lead_n++;
	if (lead <= 0) {
		late++;
	}

	/* Freeze the reference once aligned so the encode wakeup jitter does not move the
	 * point where the level is measured.
	 */
	if (!aligned) {
		lead_ref = (int32_t)lead_us;
	}

	/* Level at a fixed lead before the SDU air time, independent of this wakeup's latency */
	get_frame(left, right, true, t_tx_us - (uint32_t)(lead_ref + PHASE_GUARD_US));
#else
	ARG_UNUSED(t_tx_us);

	get_frame(left, right, false, 0U);
#endif /* CONFIG_AUDIO_INPUT_TIMED */
}

void audio_in_flush(void)
{
	(void)atomic_set(&flush_req, 1);
}

uint32_t audio_in_feedback_get(void)
{
	return (uint32_t)atomic_get(&feedback);
}

#if defined(CONFIG_AUDIO_INPUT_EMULATED)
#include <math.h>

/* 400 Hz tone at 48 kHz has a period of exactly 120 samples */
#define EMU_TONE_PERIOD 120U
#define EMU_TONE_AMP    8000.0f

static int16_t emu_tone[EMU_TONE_PERIOD];
static uint32_t emu_phase;
static uint64_t emu_t0;
static uint64_t emu_frame;
static uint32_t emu_acc;

static uint64_t emu_now_us(void)
{
#if defined(CONFIG_AUDIO_INPUT_TIMED)
	return z_nrf_grtc_timer_read();
#else
	return k_ticks_to_us_floor64((uint64_t)k_uptime_ticks());
#endif /* CONFIG_AUDIO_INPUT_TIMED */
}

static void emu_timer_handler(struct k_timer *timer)
{
	int16_t pcm[PUT_CHUNK_MAX * AUDIO_IN_CHANNELS];
	const uint64_t now = emu_now_us();

	ARG_UNUSED(timer);

	/* Emulate an asynchronous UAC2 host: each host frame, of 1 ms at the host clock, carries
	 * the samples of the accumulated feedback value.
	 */
	while (true) {
		const uint64_t host_scale = (uint64_t)(1000000 + CONFIG_AUDIO_INPUT_EMULATED_PPM);
		const uint64_t t_sof = emu_t0 +
				       ((emu_frame * USEC_PER_MSEC * 1000000ULL) / host_scale);
		uint32_t frames;

		if (t_sof > now) {
			break;
		}

		emu_acc += IS_ENABLED(CONFIG_AUDIO_INPUT_EMULATED_FEEDBACK) ?
				   audio_in_feedback_get() : AUDIO_IN_FB_NOMINAL;
		frames = MIN(emu_acc >> AUDIO_IN_FB_SHIFT, PUT_CHUNK_MAX);
		emu_acc &= BIT_MASK(AUDIO_IN_FB_SHIFT);

		for (uint32_t i = 0U; i < frames; i++) {
			pcm[i * AUDIO_IN_CHANNELS] = emu_tone[emu_phase];
			pcm[(i * AUDIO_IN_CHANNELS) + 1U] = emu_tone[emu_phase];
			emu_phase = (emu_phase + 1U) % EMU_TONE_PERIOD;
		}

		audio_in_sof((uint32_t)t_sof);
		audio_in_put(pcm, frames);
		emu_frame++;
	}
}

static K_TIMER_DEFINE(emu_timer, emu_timer_handler, NULL);

void audio_in_emulated_start(void)
{
	for (size_t i = 0U; i < EMU_TONE_PERIOD; i++) {
		emu_tone[i] = (int16_t)(EMU_TONE_AMP * sinf(2.0f * 3.14159265f * (float)i /
							    (float)EMU_TONE_PERIOD));
	}

	printk("Emulated USB host: %d ppm, feedback %s\n", CONFIG_AUDIO_INPUT_EMULATED_PPM,
	       IS_ENABLED(CONFIG_AUDIO_INPUT_EMULATED_FEEDBACK) ? "on" : "off");

	emu_t0 = emu_now_us();
	k_timer_start(&emu_timer, K_MSEC(1), K_MSEC(1));
}
#else
void audio_in_emulated_start(void)
{
}
#endif /* CONFIG_AUDIO_INPUT_EMULATED */
```

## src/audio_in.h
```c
/*
 * Copyright (c) 2025 Nordic Semiconductor ASA
 *
 * SPDX-License-Identifier: Apache-2.0
 */

#ifndef AUDIO_IN_H_
#define AUDIO_IN_H_

#include <stddef.h>
#include <stdint.h>

#include <zephyr/sys/printk.h>

/* Input stream: 48 kHz, 16-bit, interleaved stereo, delivered in 1 ms USB frames */
#define AUDIO_IN_RATE_HZ  48000U
#define AUDIO_IN_CHANNELS 2U

/* Full-speed UAC2 feedback is Q10.14 samples per 1 ms frame */
#define AUDIO_IN_FB_SHIFT   14U
#define AUDIO_IN_FB_NOMINAL ((AUDIO_IN_RATE_HZ / 1000U) << AUDIO_IN_FB_SHIFT)

/**
 * @brief Initialize the audio input path.
 *
 * @param rate_hz Broadcast sample rate; AUDIO_IN_RATE_HZ shall be a multiple of it.
 * @param frame_samples Samples per channel in one SDU (codec frame).
 *
 * @retval 0 Success
 * @retval -EINVAL Unsupported rate or frame size
 */
int audio_in_init(uint32_t rate_hz, size_t frame_samples);

/**
 * @brief Producer: push 48 kHz interleaved stereo PCM.
 *
 * Single producer context only (USB class thread or the emulated host timer).
 */
void audio_in_put(const int16_t *pcm, size_t frames);

/**
 * @brief Consumer: get one SDU frame per channel, paced by the ISO stream.
 *
 * Single consumer context only (encoder thread). Outputs silence while priming.
 */
void audio_in_get(int16_t *left, int16_t *right);

/**
 * @brief Consumer: get one SDU frame per channel, with the time the SDU is sent on air.
 *
 * Same as audio_in_get(). With CONFIG_AUDIO_INPUT_TIMED, @p t_tx_us in GRTC microseconds
 * (low 32 bits, the time base of the SOF time stamps) anchors the buffer level control to
 * the ISO stream timing.
 */
void audio_in_get_timed(int16_t *left, int16_t *right, uint32_t t_tx_us);

/**
 * @brief Producer: report a USB Start-of-Frame.
 *
 * Call from the producer context for each SOF, before the data received in that frame.
 *
 * @param t_us SOF time in GRTC microseconds (low 32 bits).
 */
void audio_in_sof(uint32_t t_us);

/** @brief Request a flush of buffered audio; any context. */
void audio_in_flush(void);

/** @brief Current feedback value in Q10.14 samples per 1 ms frame. */
uint32_t audio_in_feedback_get(void);

/**
 * @brief Consumer: print and restart the audio input metrics.
 *
 * Call from the consumer context, once per metrics interval.
 */
void audio_in_metrics_print(void);

/**
 * @brief Format a value in hundredths as a signed decimal, for metrics output.
 *
 * @param buf Output buffer.
 * @param len Size of @p buf.
 * @param v Value in hundredths.
 *
 * @return @p buf
 */
static inline const char *audio_in_centi_str(char *buf, size_t len, int64_t v)
{
	const uint64_t a = (v < 0) ? (uint64_t)(-v) : (uint64_t)v;

	(void)snprintk(buf, len, "%c%llu.%02llu", (v < 0) ? '-' : '+', a / 100U, a % 100U);

	return buf;
}

/** @brief Start the emulated USB host (CONFIG_AUDIO_INPUT_EMULATED). */
void audio_in_emulated_start(void);

#endif /* AUDIO_IN_H_ */
```

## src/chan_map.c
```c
/*
 * Copyright The Zephyr Project Contributors
 *
 * SPDX-License-Identifier: Apache-2.0
 */

/* Channel map update from the Zephyr vendor-specific Channel Metrics event.
 *
 * The controller reports, per data channel, the reception success percentage of the
 * connections and of the scanning since its previous report, filtered into a per channel
 * score. Periodically, the channels scoring at or above the threshold, topped up with the best
 * scoring channels to a minimum count, are set as the Host Channel Classification, used by the
 * extended advertising, the periodic advertising and the Broadcast ISO.
 *
 * Every reset interval all channel scores are restored, so that the full channel map is used
 * again until the metrics report a channel as bad.
 *
 * The central decides the connection channel map. Channels it excludes, at connection or by
 * a Channel Map Update procedure, are reported as bad: their score is cleared, they are not
 * restored and they are not used to reach the minimum channel count. When the central uses
 * a channel again, its score is restored.
 */

#include <stdbool.h>
#include <stdint.h>
#include <string.h>

#include <zephyr/autoconf.h>
#include <zephyr/bluetooth/bluetooth.h>
#include <zephyr/bluetooth/hci_vs.h>
#include <zephyr/kernel.h>
#include <zephyr/net_buf.h>
#include <zephyr/spinlock.h>
#include <zephyr/sys/byteorder.h>
#include <zephyr/sys/printk.h>
#include <zephyr/sys/util.h>

#include "chan_map.h"

#define CHAN_COUNT          BT_HCI_VS_CHAN_METRICS_CHAN_COUNT
#define CHAN_MAP_LEN        5U
#define SCORE_SHIFT         8U
#define SCORE_MAX           (100U << SCORE_SHIFT)
#define SCORE_THRESHOLD     ((uint32_t)CONFIG_CHAN_MAP_UPDATE_THRESHOLD << SCORE_SHIFT)
/* A report moves the score by 1/4 of its difference to the reported percentage */
#define SCORE_FILTER_SHIFT  2U

static struct k_spinlock lock;
static uint8_t pending_success[CHAN_COUNT];
static uint8_t pending_peer_map[CHAN_MAP_LEN];
static bool pending;

static uint32_t score[CHAN_COUNT];
static uint8_t peer_map[CHAN_MAP_LEN] = {0xFF, 0xFF, 0xFF, 0xFF, 0x1F};

static bool chan_is_set(const uint8_t *map, uint8_t chan)
{
	return (map[chan >> 3] & BIT(chan & 0x07U)) != 0U;
}

static void chan_map_work_handler(struct k_work *work);
static K_WORK_DELAYABLE_DEFINE(chan_map_work, chan_map_work_handler);

static void metrics_work_handler(struct k_work *work)
{
	uint8_t success[CHAN_COUNT];
	uint8_t map[CHAN_MAP_LEN];
	k_spinlock_key_t key;

	key = k_spin_lock(&lock);
	if (!pending) {
		k_spin_unlock(&lock, key);

		return;
	}
	(void)memcpy(success, pending_success, sizeof(success));
	(void)memcpy(map, pending_peer_map, sizeof(map));
	(void)memset(pending_success, BT_HCI_VS_CHAN_METRICS_NO_SAMPLES, sizeof(pending_success));
	pending = false;
	k_spin_unlock(&lock, key);

	if (memcmp(map, peer_map, sizeof(map)) != 0) {
		printk("Peer channel map 0x%010llx\n", (unsigned long long)sys_get_le40(map));

		/* Set Host Channel Classification calls are at least one second apart */
		(void)k_work_reschedule(&chan_map_work, K_SECONDS(1));
	}

	for (uint8_t i = 0U; i < CHAN_COUNT; i++) {
		uint32_t sample;

		if (!chan_is_set(map, i)) {
			score[i] = 0U;

			continue;
		}

		if (!chan_is_set(peer_map, i)) {
			score[i] = SCORE_MAX;
		}

		if (success[i] == BT_HCI_VS_CHAN_METRICS_NO_SAMPLES) {
			continue;
		}

		sample = (uint32_t)MIN(success[i], 100U) << SCORE_SHIFT;
		if (sample >= score[i]) {
			score[i] += (sample - score[i]) >> SCORE_FILTER_SHIFT;
		} else {
			score[i] -= (score[i] - sample) >> SCORE_FILTER_SHIFT;
		}
	}

	(void)memcpy(peer_map, map, sizeof(peer_map));
}

static K_WORK_DEFINE(metrics_work, metrics_work_handler);

bool chan_map_vnd_evt(struct net_buf_simple *buf)
{
	const struct bt_hci_evt_vs_chan_metrics *evt;
	const struct bt_hci_evt_vs *vs;
	k_spinlock_key_t key;

	if (buf->len < (sizeof(*vs) + sizeof(*evt))) {
		return false;
	}

	vs = net_buf_simple_pull_mem(buf, sizeof(*vs));
	if (vs->subevent != BT_HCI_EVT_VS_CHAN_METRICS) {
		return false;
	}

	evt = net_buf_simple_pull_mem(buf, sizeof(*evt));

	/* Keep a not yet filtered report of a channel that has no samples in this report */
	key = k_spin_lock(&lock);
	for (uint8_t i = 0U; i < CHAN_COUNT; i++) {
		if (evt->success[i] != BT_HCI_VS_CHAN_METRICS_NO_SAMPLES) {
			pending_success[i] = evt->success[i];
		}
	}
	(void)memcpy(pending_peer_map, evt->chan_map, sizeof(pending_peer_map));
	pending = true;
	k_spin_unlock(&lock, key);

	(void)k_work_submit(&metrics_work);

	return true;
}

static void chan_map_work_handler(struct k_work *work)
{
	static uint8_t map_curr[CHAN_MAP_LEN] = {0xFF, 0xFF, 0xFF, 0xFF, 0x1F};
	static int64_t reset_uptime;
	struct k_work_delayable *dwork = k_work_delayable_from_work(work);
	uint8_t map[CHAN_MAP_LEN] = {0U};
	uint8_t count = 0U;
	int err;

	if ((k_uptime_get() - reset_uptime) >= (CONFIG_CHAN_MAP_RESET_INTERVAL * MSEC_PER_SEC)) {
		reset_uptime = k_uptime_get();

		for (uint8_t i = 0U; i < CHAN_COUNT; i++) {
			if (chan_is_set(peer_map, i)) {
				score[i] = SCORE_MAX;
			}
		}
	}

	for (uint8_t i = 0U; i < CHAN_COUNT; i++) {
		if (chan_is_set(peer_map, i) && (score[i] >= SCORE_THRESHOLD)) {
			map[i >> 3] |= BIT(i & 0x07U);
			count++;
		}
	}

	/* A peer Central uses at least 2 channels, channels it excludes are not added */
	while (count < CONFIG_CHAN_MAP_UPDATE_CHAN_MIN) {
		bool found = false;
		uint8_t best = 0U;

		for (uint8_t i = 0U; i < CHAN_COUNT; i++) {
			if (chan_is_set(peer_map, i) && !chan_is_set(map, i) &&
			    (!found || (score[i] > score[best]))) {
				best = i;
				found = true;
			}
		}

		if (!found) {
			break;
		}

		map[best >> 3] |= BIT(best & 0x07U);
		count++;
	}

	if (memcmp(map, map_curr, sizeof(map)) != 0) {
		err = bt_le_set_chan_map(map);
		if (err == 0) {
			(void)memcpy(map_curr, map, sizeof(map_curr));
			printk("Channel map 0x%010llx, %u channels\n",
			       (unsigned long long)sys_get_le40(map), count);
		} else {
			/* Retried next interval, e.g. while a BIG channel map update is pending */
			printk("Failed to set channel map (err %d)\n", err);
		}
	}

	(void)k_work_reschedule(dwork, K_SECONDS(CONFIG_CHAN_MAP_UPDATE_INTERVAL));
}

void chan_map_init(void)
{
	for (uint8_t i = 0U; i < CHAN_COUNT; i++) {
		score[i] = SCORE_MAX;
	}
	(void)memset(pending_success, BT_HCI_VS_CHAN_METRICS_NO_SAMPLES, sizeof(pending_success));
	(void)memcpy(pending_peer_map, peer_map, sizeof(pending_peer_map));

	(void)k_work_schedule(&chan_map_work, K_SECONDS(CONFIG_CHAN_MAP_UPDATE_INTERVAL));
}
```

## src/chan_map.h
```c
/*
 * Copyright The Zephyr Project Contributors
 *
 * SPDX-License-Identifier: Apache-2.0
 */

#ifndef CHAN_MAP_H_
#define CHAN_MAP_H_

struct net_buf_simple;

/**
 * @brief Start the channel metrics based channel map update.
 *
 * Call after bt_enable().
 */
void chan_map_init(void);

/**
 * @brief Collect a Channel Metrics vendor-specific event.
 *
 * @param buf Vendor-specific event, starting with the subevent code.
 *
 * @retval true The event is a Channel Metrics event and was collected
 * @retval false The event is not a Channel Metrics event
 */
bool chan_map_vnd_evt(struct net_buf_simple *buf);

#endif /* CHAN_MAP_H_ */
```

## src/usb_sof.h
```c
/*
 * Copyright (c) 2025 Nordic Semiconductor ASA
 *
 * SPDX-License-Identifier: Apache-2.0
 */

#ifndef USB_SOF_H_
#define USB_SOF_H_

#include <stdint.h>

/**
 * @brief Route the USB SOF event to a GRTC capture channel.
 *
 * @retval 0 Success
 * @retval -ENOMEM No GRTC channel or DPPI connection available
 */
int usb_sof_init(void);

/**
 * @brief Read and re-arm the SOF capture.
 *
 * @param t_us Time of the last captured SOF in GRTC microseconds (low 32 bits).
 *
 * @retval 0 Success
 * @retval -EBUSY No SOF captured since the last read
 * @retval -ENODEV Not initialized
 */
int usb_sof_read(uint32_t *t_us);

#endif /* USB_SOF_H_ */
```

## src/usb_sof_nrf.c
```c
/*
 * Copyright (c) 2025 Nordic Semiconductor ASA
 *
 * SPDX-License-Identifier: Apache-2.0
 *
 * USB Start-of-Frame time stamping on nRF54LM20: the USBHS wrapper publishes the SOF event on
 * DPPI, which triggers a capture of the GRTC SYSCOUNTER, the time base of the Bluetooth
 * controller. The capture is read and re-armed from the UAC2 SOF callback.
 */

#include <errno.h>
#include <stdint.h>

#include <zephyr/devicetree.h>
#include <zephyr/drivers/timer/nrf_grtc_timer.h>
#include <zephyr/sys/printk.h>

#include <nrfx.h>
#include <helpers/nrfx_gppi.h>

#include "usb_sof.h"

#define USBHS_WRAPPER ((NRF_USBHS_Type *)DT_REG_ADDR(DT_NODELABEL(usbhs_wrapper)))

/* The USBHS wrapper has a PUBLISH_SOF register but no EVENTS_SOF register; GPPI locates the
 * publish register at the event address plus the publish offset.
 */
#define USBHS_SOF_EVENT_ADDRESS                                                                    \
	((uint32_t)&USBHS_WRAPPER->PUBLISH_SOF -                                                   \
	 NRF_SUBSCRIBE_PUBLISH_OFFSET((uint32_t)&USBHS_WRAPPER->PUBLISH_SOF))

static int32_t grtc_chan = -1;

int usb_sof_init(void)
{
	nrfx_gppi_handle_t handle;
	int err;

	grtc_chan = z_nrf_grtc_timer_chan_alloc();
	if (grtc_chan < 0) {
		printk("USB SOF: no GRTC channel: %d\n", grtc_chan);
		return grtc_chan;
	}

	err = z_nrf_grtc_timer_capture_prepare(grtc_chan);
	if (err != 0) {
		printk("USB SOF: GRTC capture prepare failed: %d\n", err);
		return err;
	}

	err = nrfx_gppi_conn_alloc(USBHS_SOF_EVENT_ADDRESS,
				   z_nrf_grtc_timer_capture_task_address_get(grtc_chan), &handle);
	if (err != 0) {
		printk("USB SOF: GPPI connection failed: %d\n", err);
		return err;
	}

	nrfx_gppi_conn_enable(handle);

	printk("USB SOF: GRTC channel %d\n", grtc_chan);

	return 0;
}

int usb_sof_read(uint32_t *t_us)
{
	uint64_t captured;
	int err;

	if (grtc_chan < 0) {
		return -ENODEV;
	}

	err = z_nrf_grtc_timer_capture_read(grtc_chan, &captured);
	if (err != 0) {
		return err;
	}

	(void)z_nrf_grtc_timer_capture_prepare(grtc_chan);

	/* The controller uses the low 32 bits of the 1 MHz SYSCOUNTER */
	*t_us = (uint32_t)captured;

	return 0;
}
```

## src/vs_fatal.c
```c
/*
 * Copyright (c) 2026 Nordic Semiconductor ASA
 *
 * SPDX-License-Identifier: Apache-2.0
 */

#include <stdbool.h>
#include <stdint.h>
#include <string.h>

#include <zephyr/bluetooth/hci_vs.h>
#include <zephyr/fatal_types.h>
#include <zephyr/logging/log_ctrl.h>
#include <zephyr/net_buf.h>
#include <zephyr/sys/byteorder.h>
#include <zephyr/sys/printk.h>

#include "vs_fatal.h"

static const char *fatal_reason_str(uint32_t reason)
{
	switch (reason) {
	case K_ERR_CPU_EXCEPTION:
		return "CPU exception";
	case K_ERR_SPURIOUS_IRQ:
		return "spurious interrupt";
	case K_ERR_STACK_CHK_FAIL:
		return "stack overflow";
	case K_ERR_KERNEL_OOPS:
		return "kernel oops";
	case K_ERR_KERNEL_PANIC:
		return "kernel panic";
	default:
		return "unknown";
	}
}

static bool stack_frame_decode(struct net_buf_simple *buf)
{
	const struct bt_hci_vs_fatal_error_cpu_data_cortex_m *cpu;
	const struct bt_hci_vs_fatal_error_stack_frame *sf;
	uint32_t reason;

	if (buf->len != (sizeof(*sf) + sizeof(*cpu))) {
		return false;
	}

	sf = net_buf_simple_pull_mem(buf, sizeof(*sf));
	if (sf->cpu_type != BT_HCI_EVT_VS_ERROR_CPU_TYPE_CORTEX_M) {
		return false;
	}

	cpu = net_buf_simple_pull_mem(buf, sizeof(*cpu));
	reason = sys_le32_to_cpu(sf->reason);

	printk("Controller fatal error: reason %u (%s), Cortex-M stack frame:\n", reason,
	       fatal_reason_str(reason));
	printk("  r0/a1 0x%08x  r1/a2 0x%08x  r2/a3 0x%08x  r3/a4 0x%08x\n",
	       sys_le32_to_cpu(cpu->a1), sys_le32_to_cpu(cpu->a2), sys_le32_to_cpu(cpu->a3),
	       sys_le32_to_cpu(cpu->a4));
	printk("  r12/ip 0x%08x  r14/lr 0x%08x\n", sys_le32_to_cpu(cpu->ip),
	       sys_le32_to_cpu(cpu->lr));
	printk("  r15/pc 0x%08x (faulting instruction)  xpsr 0x%08x\n", sys_le32_to_cpu(cpu->pc),
	       sys_le32_to_cpu(cpu->xpsr));

	return true;
}

/* File name, NUL terminated, followed by the little-endian 32-bit line number */
static bool file_line_decode(struct net_buf_simple *buf, const char *kind, bool has_pc)
{
	const char *file;
	uint64_t pc = 0U;
	uint32_t line;
	size_t len;

	if (has_pc) {
		if (buf->len < sizeof(uint64_t)) {
			return false;
		}

		pc = net_buf_simple_pull_le64(buf);
	}

	if (buf->len < (sizeof(uint32_t) + 1U)) {
		return false;
	}

	len = buf->len - sizeof(uint32_t);
	file = (const char *)buf->data;
	if ((file[len - 1U] != '\0') || (strlen(file) != (len - 1U))) {
		return false;
	}

	(void)net_buf_simple_pull_mem(buf, len);
	line = net_buf_simple_pull_le32(buf);

	if (has_pc) {
		printk("Controller %s: %s:%u, pc 0x%08x%08x\n", kind, file, line,
		       (uint32_t)(pc >> 32), (uint32_t)pc);
	} else {
		printk("Controller %s: %s:%u\n", kind, file, line);
	}

	return true;
}

bool vs_fatal_vnd_evt(struct net_buf_simple *buf)
{
	uint8_t type;
	bool handled;

	if (buf->len < 1U) {
		return false;
	}

	type = net_buf_simple_pull_u8(buf);
	switch (type) {
	case BT_HCI_EVT_VS_ERROR_DATA_TYPE_STACK_FRAME:
		handled = stack_frame_decode(buf);
		break;

	case BT_HCI_EVT_VS_ERROR_DATA_TYPE_CTRL_ASSERT:
		handled = file_line_decode(buf, "assert", false);
		break;

	case BT_HCI_EVT_VS_ERROR_DATA_TYPE_TRACE:
		/* Shares its code with the Trace Info subevent, decoded only when well formed */
		handled = file_line_decode(buf, "fatal error trace", true);
		break;

	default:
		handled = false;
		break;
	}

	if (handled) {
		/* The Controller has halted, output the decoded fatal error synchronously */
		LOG_PANIC();
	}

	return handled;
}
```

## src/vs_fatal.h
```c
/*
 * Copyright (c) 2026 Nordic Semiconductor ASA
 *
 * SPDX-License-Identifier: Apache-2.0
 */

#ifndef VS_FATAL_H_
#define VS_FATAL_H_

struct net_buf_simple;

/**
 * @brief Decode a Controller fatal error vendor-specific event.
 *
 * @param buf Vendor-specific event, starting with the subevent code.
 *
 * @retval true The event is a Controller fatal error event and was printed
 * @retval false The event is not a Controller fatal error event
 */
bool vs_fatal_vnd_evt(struct net_buf_simple *buf);

#endif /* VS_FATAL_H_ */
```
